# STM32F469 register map
File version: 1.9
CPU: CM4 r0p1, little endian, MPU, FPU, 4 interrupt priority bits
Registers are 32-bit, read-write, reset 0x0 unless marked. A register's access mark holds for its fields unless they carry their own. Offsets are from the block's base; [hi:lo] are bit positions; {n}, {i} and the like mark numbered series.

## FLASH
Base 0x40023C00
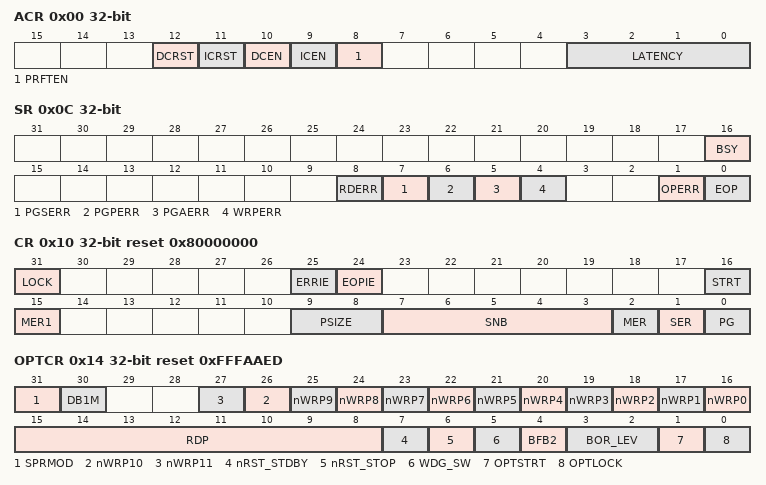
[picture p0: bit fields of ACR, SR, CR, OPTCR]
0x00 ACR access per field — Flash access control register
  [12] DCRST rw — Data cache reset
    0=NoReset (Data cache is not reset); 1=Reset (Data cache is reset)
  [11] ICRST wo — Instruction cache reset
    0=NoReset (Instruction cache is not reset); 1=Reset (Instruction cache is reset)
  [10] DCEN rw — Data cache enable
    0=Disabled (Data cache is disabled); 1=Enabled (Data cache is enabled)
  [9] ICEN rw — Instruction cache enable
    0=Disabled (Instruction cache is disabled); 1=Enabled (Instruction cache is enabled)
  [8] PRFTEN rw — Prefetch enable
    0=Disabled (Prefetch is disabled); 1=Enabled (Prefetch is enabled)
  [3:0] LATENCY rw
    {v}=WS{v} ({v} wait states) (v=0..15)
0x04 KEYR wo — Flash key register
  [31:0] KEY — FPEC key
0x08 OPTKEYR wo — Flash option key register
  [31:0] OPTKEYR — Option byte key
0x0C SR access per field — Status register
  [16] BSY ro — Busy
    0=NotBusy (No Flash memory operation ongoing); 1=Busy (Flash memory operation ongoing)
  [8] RDERR rw write-1-clears — Proprietary readout protection (PCROP) error
    on read: 0=Inactive (No error); 1=Active (A read access through the D-bus is performed to an address belonging to a proprietary readout protected Flash sector) | on write: 1=Clear error flag
  [7] PGSERR rw write-1-clears — Programming sequence error
    on read: 0=Inactive (No error); 1=Active (A write access to the Flash memory is performed by the code while the control register has not been correctly configured) | on write: 1=Clear error flag
  [6] PGPERR rw write-1-clears — Programming parallelism error
    on read: 0=Inactive (No error); 1=Active (The size of the access during the program sequence doesn't correspond to the parallelism configuration PSIZE) | on write: 1=Clear error flag
  [5] PGAERR rw write-1-clears — Programming alignment error
    on read: 0=Inactive (No error); 1=Active (The data to program cannot be contained in the same 128-bit Flash memory row) | on write: 1=Clear error flag
  [4] WRPERR rw write-1-clears — Write protection error
    on read: 0=Inactive (No error); 1=Active (The address to be erased/programmed belongs to a write-protected part of the Flash memory) | on write: 1=Clear error flag
  [1] OPERR rw write-1-clears — Operation error
    on read: 0=Inactive (No error); 1=Active (A Flash operation request is detected and cannot be run because of parallelism) | on write: 1=Clear error flag
  [0] EOP rw write-1-clears — End of operation
    on read: 0=Inactive (No error); 1=Active (One or more Flash operations has/have completed successfully) | on write: 1=Clear error flag
0x10 CR reset 0x80000000 — Control register
  [31] LOCK
    0=Unlocked (FLASH_CR register is unlocked); 1=Locked (FLASH_CR register is locked)
  [25] ERRIE — Error interrupt enable
    0=Disabled (Error interrupt generation disabled); 1=Enabled (Error interrupt generation enabled)
  [24] EOPIE — End of operation interrupt enable
    0=Disabled (End of operation interrupt disabled); 1=Enabled (End of operation interrupt enabled)
  [16] STRT — Start
    1=Start (Trigger an erase operation)
  [15] MER1 — Mass Erase of sectors 12 to 23
    1=MassErase (Erase activated for bank 2 sectors)
  [9:8] PSIZE — Program size
    0=Program x8; 1=Program x16; 2=Program x32; 3=Program x64
  [7:3] SNB range 0..11 — Sector number
  [2] MER — Mass Erase of sectors 0 to 11
    1=MassErase (Erase activated for bank 1 sectors)
  [1] SER — Sector Erase
    1=SectorErase (Erase activated for selected sector)
  [0] PG — Programming
    1=Program (Flash programming activated)
0x14 OPTCR reset 0xFFFAAED — Flash option control register
  [31] SPRMOD — Selection of protection mode for nWPRi bits
    0=Disabled (nWPRi bits used for Write protection on sector i); 1=Enabled (nWPRi bits used for PCROP protection on sector i)
  [30] DB1M — Dual-bank on 1 Mbyte Flash memory devices
    0=Single bank with contiguous addresses in bank 1; 1=Dual bank with two banks of 512kB
  [n+16] nWRP{n} (n=0..11) — Not write protect
    0=Active (Write protection active on sector %s); 1=Inactive (Write protection inactive on sector %s)
  [15:8] RDP — Read protect
    170=Level0 (Read protection not active); 204=Level2 (Chip read protection active); other=Level1 (Read protection of memories active)
  [7] nRST_STDBY — nRST_STDBY User option bytes
    0=Reset generated when entering Standby mode; 1=No reset generated
  [6] nRST_STOP — nRST_STOP User option bytes
    0=Reset generated when entering Stop mode; 1=No reset generated
  [5] WDG_SW — WDG_SW User option bytes
    0=Hardware watchdog; 1=Software watchdog
  [4] BFB2 — Dual-bank Boot option byte
    0=Disabled (Dual-bank boot disabled); 1=Enabled (Dual-bank boot enabled)
  [3:2] BOR_LEV — BOR reset Level
    0=BOR_Off (Reset threshold level for POR/PDR (around 1.7V)); 1=BOR_Level1 (Reset threshold level for VBOR1 (around 2.2 V)); 2=BOR_Level2 (Reset threshold level for VBOR2 (around 2.5 V)); 3=BOR_Level3 (Reset threshold level for VBOR3 (around 2.8 V))
  [1] OPTSTRT — Option start
    on read: 0=Complete (Cleared when BSY bit is cleared in SR); 1=Requested (Options modification requested) | on write: 1=Set (This bit triggers an options operation when set)
  [0] OPTLOCK — Option lock
    on read: 0=Unlocked (The write and erase operations in the Option bytes area are disabled); 1=Locked (The write and erase operations in the Option bytes area are enabled) | on write: 1=Set (Lock the FLASH_OPTCR register)
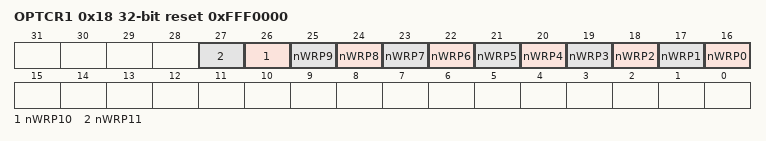
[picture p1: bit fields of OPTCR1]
0x18 OPTCR1 reset 0xFFF0000 — Flash option control register 1
  [n+16] nWRP{n} (n=0..11) — Not write protect
    0=Active (Write protection active on sector %s (bank 2)); 1=Inactive (Write protection inactive on sector %s (bank 2))
